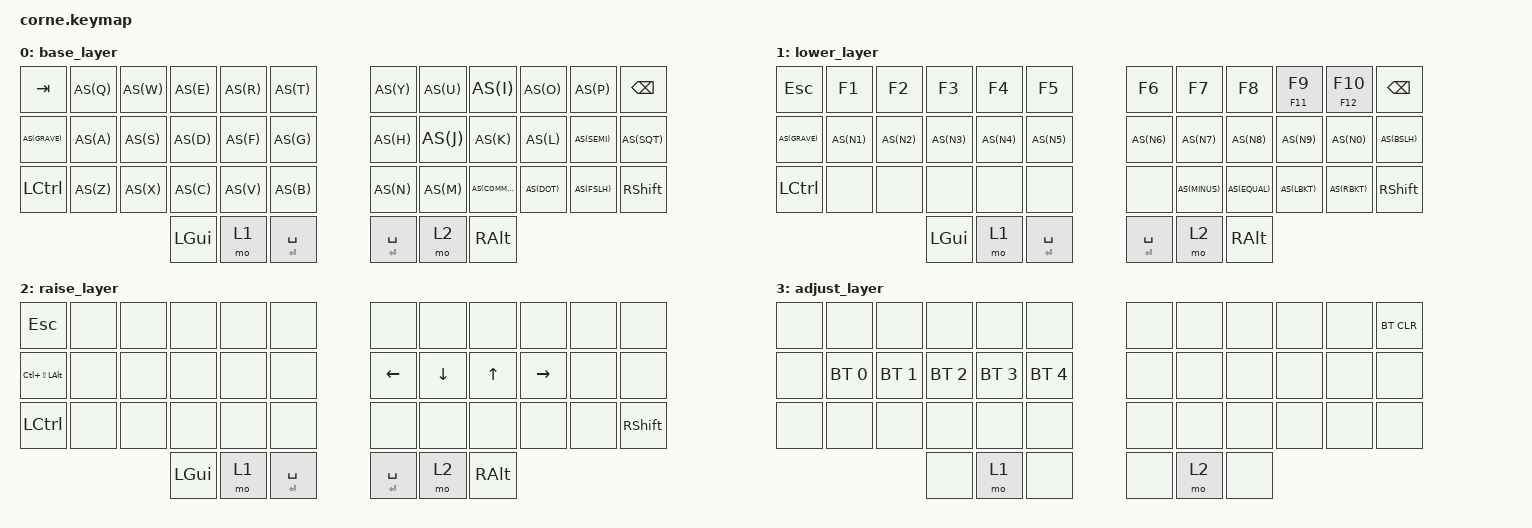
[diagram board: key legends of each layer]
#include <behaviors.dtsi>
#include <dt-bindings/zmk/keys.h>
#include <dt-bindings/zmk/bt.h>

// Aliases
#define LOWER &mo 1
#define RAISE &mo 2
#define MEH &kp LC(LS(LALT))
#define BT_1 &bt BT_SEL 0
#define BT_2 &bt BT_SEL 1
#define BT_3 &bt BT_SEL 2
#define BT_4 &bt BT_SEL 3
#define BT_5 &bt BT_SEL 4
// Macros
#define AS(keycode) &as LS(keycode) keycode  // auto-shift
#define SPC_ENTR &tm RETURN SPACE            // tap = space, hold = enter

/ {
    behaviors {
      as: auto_shift {
        compatible = "zmk,behavior-hold-tap";
        #binding-cells = <2>;
        tapping_term_ms = <200>;
        quick_tap_ms = <0>;
        flavor = "tap-preferred";
        bindings = <&kp>, <&kp>;
      };
      // mod_tap (&mt) but tap-preferred
      tm: tap_mod {
        compatible = "zmk,behavior-hold-tap";
        #binding-cells = <2>;
        flavor = "tap-preferred";
        tapping-term-ms = <200>;
        bindings = <&kp>, <&kp>;
      };
    };
    conditional_layers {
      compatible = "zmk,conditional-layers";
      activate_adjust_layer {
        if-layers = <1 2>; // lower + raise
        then-layer = <3>;  // adjust
      };
    };

    keymap {
      compatible = "zmk,keymap";
      base_layer {
        // -----------------------------------------------------------------------------------------
        // |  TAB |  Q  |  W  |  E  |  R  |  T  |       |  Y  |  U   |  I  |  O  |  P  | BSPC |
        // |   `  |  A  |  S  |  D  |  F  |  G  |       |  H  |  J   |  K  |  L  |  ;  |  '   |
        // | CTRL |  Z  |  X  |  C  |  V  |  B  |       |  N  |  M   |  ,  |  .  |  /  | SHFT |
        //                    | CMD | LWR | ␣/⏎ |       | ␣/⏎ | RSE  | ALT |
        bindings = <
          &kp TAB   AS(Q) AS(W) AS(E) AS(R) AS(T)       AS(Y) AS(U) AS(I)     AS(O)   AS(P)    &kp BSPC
          AS(GRAVE) AS(A) AS(S) AS(D) AS(F) AS(G)       AS(H) AS(J) AS(K)     AS(L)   AS(SEMI) AS(SQT)
          &kp LCTRL AS(Z) AS(X) AS(C) AS(V) AS(B)       AS(N) AS(M) AS(COMMA) AS(DOT) AS(FSLH) &kp RSHFT
                         &kp LGUI  LOWER  SPC_ENTR    SPC_ENTR  RAISE  &kp RALT
        >;
      };
      lower_layer {
        // -----------------------------------------------------------------------------------------
        // |  ESC | F1  | F2  | F3  | F4  | F5  |       | F6  | F7  | F8  | F9/11 | F10/12  | BSPC |
        // |   `  |  1  |  2  |  3  |  4  |  5  |       |  6  |  7  |  8  |  9    |  0      |  \   |
        // | CTRL |  ×  |  ×  |  ×  |  ×  |  ×  |       |  ×  |  -  |  =  |  [    |  ]      | SHFT |
        //                    | CMD |     | ␣/⏎ |       | ␣/⏎ |     | ALT |
        bindings = <
          &kp ESC   &kp F1 &kp F2 &kp F3 &kp F4 &kp F5        &kp F6 &kp F7    &kp F8    &mt F11 F9 &mt F12 F10 &kp BSPC
          AS(GRAVE) AS(N1) AS(N2) AS(N3) AS(N4) AS(N5)        AS(N6) AS(N7)    AS(N8)    AS(N9)     AS(N0)      AS(BSLH)
          &kp LCTRL &none  &none  &none  &none  &none         &none  AS(MINUS) AS(EQUAL) AS(LBKT)   AS(RBKT)    &kp RSHFT
                              &kp LGUI LOWER SPC_ENTR    SPC_ENTR  RAISE &kp RALT
        >;
      };
      raise_layer {
        // -----------------------------------------------------------------------------------------
        // |  ESC |  ×  |  ×  |  ×  |  ×  |  ×  |       |  ×  |  ×  |  ×  |  ×  |  ×  |  ×   |
        // |  MEH |  ×  |  ×  |  ×  |  ×  |  ×  |       |  ←  |  ↓  |  ↑  |  →  |  ×  |  ×   | 
        // | CTRL |  ×  |  ×  |  ×  |  ×  |  ×  |       |  ×  |  ×  |  ×  |  ×  |  ×  | SHFT |
        //                    | GUI |     | ␣/⏎ |       | ␣/⏎ |     | ALT |
        bindings = <
          &kp ESC    &none  &none  &none  &none  &none         &none     &none     &none   &none      &none  &none
          MEH        &none  &none  &none  &none  &none         &kp LEFT  &kp DOWN  &kp UP  &kp RIGHT  &none  &none
          &kp LCTRL  &none  &none  &none  &none  &none         &none     &none     &none   &none      &none  &kp RSHFT
                              &kp LGUI LOWER SPC_ENTR   SPC_ENTR  RAISE  &kp RALT
        >;
      };
      adjust_layer {
        // -----------------------------------------------------------------------------------------
        // |   ×  |  ×  |  ×  |  ×  |  ×  |  ×  |       |  ×  |  ×  |  ×  |  ×  |  ×  | BTCLR |
        // |   ×  | BT1 | BT2 | BT3 | BT4 | BT5 |       |  ×  |  ×  |  ×  |  ×  |  ×  |   ×   |
        // |   ×  |  ×  |  ×  |  ×  |  ×  |  ×  |       |  ×  |  ×  |  ×  |  ×  |  ×  |   ×   |
        //                    |  ×  |     |  ×  |       |  ×  |     |  ×  |
        bindings = <
           &none  &none  &none  &none  &none  &none         &none  &none  &none  &none  &none  &bt BT_CLR
           &none  BT_1   BT_2   BT_3   BT_4   BT_5          &none  &none  &none  &none  &none  &none
           &none  &none  &none  &none  &none  &none         &none  &none  &none  &none  &none  &none
                                  &none LOWER  &none   &none  RAISE  &none
        >;
      };
    };
};
